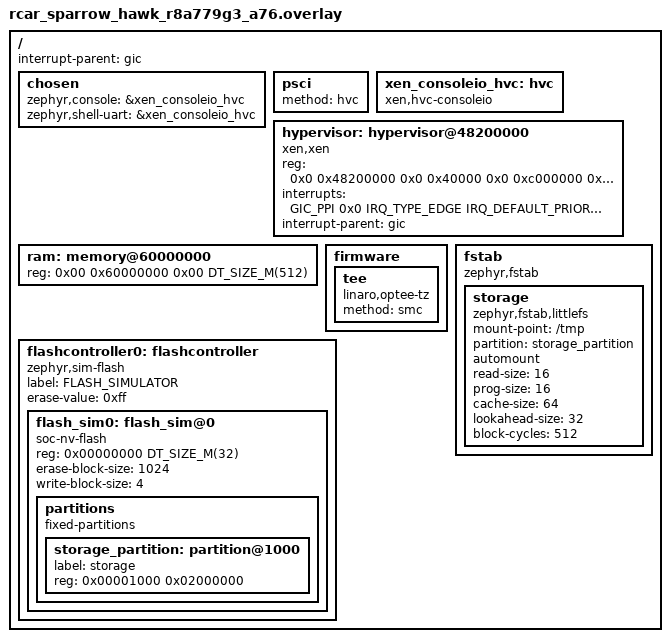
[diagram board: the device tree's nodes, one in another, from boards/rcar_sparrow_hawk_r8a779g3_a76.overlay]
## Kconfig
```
# Copyright (c) 2024 EPAM Systems
#
# SPDX-License-Identifier: Apache-2.0


config DOMD_ENABLE
	bool "Enable builtin Domain-U1 kernel binary"
	default n

config DOMD_UBOOT_PATH
	string "Location for Domain-U1 kernel binary"
	depends on DOMD_ENABLE
        default "\"/path/to/uboot/file\""

config DOMD_DTB_PATH
	string "Location for Domain-U1 device-tree"
	depends on DOMD_ENABLE
        default "\"/path/to/dtb/file\""

config DOMU_ENABLE
	bool "Enable builtin Domain-U1 kernel binary"
	default n

config DOMU_ZEPHYR_PATH
	string "Location for Domain-U1 kernel binary"
	depends on DOMU_ENABLE
        default "\"/path/to/uboot/file\""

config DOMU_DTB_PATH
	string "Location for Domain-U1 device-tree"
	depends on DOMU_ENABLE
        default "\"/path/to/dtb/file\""


config USE_DEFAULT_DOM_CFG
	bool "Use default guest domain cfg"
	default y
	help
	  Use default guest domain cfg from domu_cfg.c for build.
	  if not selected the guest domain cfg source file will be selected as basing
	  on board/platform:
	    dom_cfg/${BOARD}.c.
	  For example, for RPI 5 the dom_cfg/rpi_5.c will be used.

config DOM_CFG_BOARD_EXT
	string "Use extention string to determine guest domain cfg"
	depends on !USE_DEFAULT_DOM_CFG
	help
	  Use it to add extention string to determine guest domain cfg file to build.
	  The guest domain cfg source file will be selected as following:
	    dom_cfg/${BOARD}_${DOM_CFG_BOARD_EXT}.c
	  This allows to specify number of guest domain configs for the same board.
	  For example:
	    rpi_5_xenvm.c
	    rpi_5_domu.c

config DOM_STORAGE_FATFS_ENABLE
	bool "Enable FATFS disk storage for reading domains kernels/dtb images"
	default n
	select DISK_ACCESS
	select FILE_SYSTEM
	select FAT_FILESYSTEM_ELM
	select XRUN
	help
	  Enables FATFS disk storage and adds possibility to read guest domains
	  kernels/dtb images from storage.

if DOM_STORAGE_FATFS_ENABLE

config FS_FATFS_MOUNT_MKFS
	default n

config FS_FATFS_WINDOW_ALIGNMENT
	default SDHC_BUFFER_ALIGNMENT

config FS_FATFS_LBA64
	default y

config FS_FATFS_EXFAT
	default y

config DOM_STORAGE_FATFS_DIR
	string "FATFS folder where domains kernels/dtb images"
	default "dom0/"
	help
	  FATFS folder where domains kernels/dtb images are located.
	  It should be ended with "/" symbol.

config DOM_STORAGE_FATFS_LOGICAL_DRIVE_NAME
	string "FATFS logical drive name to be used as mount point"
	default "0" if FS_MULTI_PARTITION
	default SDMMC_VOLUME_NAME
	help
	  FATFS logical drive name to be used as mount point.

config DOM_CFG_LINUX_PV_DOMAIN
	bool "Enable PV domain support loaded from FATFS storage"
	help
	  Adds Linux-based domain with enabled pvnet and pvblock devices.
	  It is expected to be placed on the storage device, connected to
	  Dom0.

endif #DOM_STORAGE_FATFS_ENABLE

config DOM_CFG_BUILTIN_IMAGES
	bool "Use built-in guest domains kernel/device-tree images"
	default y
	help
	  Use built-in guest domains kernel/device-tree images.

if DOM_CFG_BUILTIN_IMAGES

config DOM_CFG_DOMU0_IMAGE_BIN_FILE
	string "Location for Domain-U0 kernel binary"
	default "domu0_img.bin"

config DOM_CFG_DOMU0_DTB_BIN_FILE
	string "Location for Domain-U0 device-tree"
	default "domu0.dtb"

config DOM_CFG_DOMU1_ENABLE
	bool "Enable builtin Domain-U1 kernel binary"
	default n

config DOM_CFG_DOMU1_IMAGE_BIN_FILE
	string "Location for Domain-U1 kernel binary"
	depends on DOM_CFG_DOMU1_ENABLE

config DOM_CFG_DOMU1_DTB_BIN_FILE
	string "Location for Domain-U1 device-tree"
	depends on DOM_CFG_DOMU1_ENABLE

endif #DOM_CFG_BUILTIN_IMAGES

config DOM_COVERAGE_ENABLE
	bool "Enable code coverage with GCOV"
	depends on SHELL
	select FORCE_COVERAGE
	select COVERAGE
	help
	  Enable code coverage with GCOV and enable shell command to print GCOV
	  dump "gcov dump" in console.

config VCHAN_SHELL_CMDS
	depends on SHELL
	bool "Enable VCHAN echo server shell commands"
	help
	  Enable set of VCHAN echo server shell commands. All data incoming to
	  channel created by this server will be send back. This is for test
	  purposes. Server introduces 2 commands:
	  vchan start [domid]
	    Start echo server. domid - The peer domain that will be connecting
	    (0 by default)
	  vchan stop
	    Stop server

if VCHAN_SHELL_CMDS

config VCHAN_ECHO_BUFFER_SIZE
	int "Buffer size for echo server"
	default 10

config VCHAN_THREAD_STACK_SIZE
	int "vchan echo server thread size"
	default 2048

endif #VCHAN_SHELL_CMDS

source "Kconfig.zephyr"
```

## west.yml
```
# SPDX-License-Identifier: Apache-2.0
# West YAML manifest for Zephyr as Xen Dom0

manifest:
  self:
    path: zephyr-dom0-xt

  remotes:
    - name: xentroops
      url-base: https://github.com/xen-troops/
    - name: zephyrproject-rtos
      url-base: https://github.com/zephyrproject-rtos/
    - name: yhamamachi
      url-base: https://github.com/yhamamachi/
    - name: soburi
      url-base: https://github.com/soburi/

  projects:
    - name: zephyr
      remote: yhamamachi
      revision: v4.3.0-sh
      west-commands: scripts/west-commands.yml
    - name: zephyr-xenlib
      remote: soburi
      revision: integrate-to-zephyr-repo
    - name: fatfs
      remote: zephyrproject-rtos
      revision: 427159bf95ea49b7680facffaa29ad506b42709b
    - name: zephyr-xrun
      remote: xentroops
      revision: main
```

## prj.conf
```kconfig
CONFIG_XEN_DOM0=y
CONFIG_UART_INTERRUPT_DRIVEN=n
CONFIG_SHELL_BACKEND_SERIAL_INTERRUPT_DRIVEN=n

CONFIG_MP_MAX_NUM_CPUS=1
CONFIG_XEN_STORE_SRV=y
CONFIG_XEN_DOMAIN_MANAGEMENT=y
CONFIG_XEN_SHELL=y
CONFIG_XEN_CONSOLE_SRV=y
CONFIG_HEAP_MEM_POOL_SIZE=2097152
CONFIG_SHELL_STACK_SIZE=4096

CONFIG_LOG=y
CONFIG_LOG_MODE_MINIMAL=y
CONFIG_XEN_DOMCTL_INTERFACE_VERSION=0x16
#CONFIG_LOG_DEFAULT_LEVEL=4
```

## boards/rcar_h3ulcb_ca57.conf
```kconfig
#
# Copyright (c) 2023 EPAM Systems
#
# SPDX-License-Identifier: Apache-2.0
#

# Kernel virtual memory size

# CONFIG_KERNEL_VM_SIZE=0x4000000
# CONFIG_PARTIAL_DEVICE_TREE_SIZE=80000
# 
# CONFIG_SHELL_STACK_SIZE=8192
# 
# CONFIG_XEN_DOM0=y

CONFIG_XEN_DOM0=y

CONFIG_XSTAT=y
CONFIG_XSTAT_SHELL_CMDS=y

CONFIG_SHELL_STACK_SIZE=4096

CONFIG_MAIN_STACK_SIZE=8192
CONFIG_ISR_STACK_SIZE=8192

CONFIG_XEN_VCH=y
#CONFIG_XEN_DOM0LESS_BOOT=y

CONFIG_USE_DEFAULT_DOM_CFG=n
CONFIG_DOM_CFG_BUILTIN_IMAGES=n

CONFIG_FILE_SYSTEM_SHELL=y

CONFIG_XRUN_STORAGE_DMA_DEBOUNCE=4

CONFIG_DOM_MAX=5
CONFIG_SHELL=y

CONFIG_NOCACHE_MEMORY=y
CONFIG_XEN_LIBFDT=y
CONFIG_PARTIAL_DEVICE_TREE_SIZE=1024000
```

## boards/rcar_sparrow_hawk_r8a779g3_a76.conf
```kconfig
#
# Copyright (c) 2023 EPAM Systems
#
# SPDX-License-Identifier: Apache-2.0
#

# Kernel virtual memory size

# CONFIG_KERNEL_VM_SIZE=0x4000000
# CONFIG_PARTIAL_DEVICE_TREE_SIZE=80000
# 
# CONFIG_SHELL_STACK_SIZE=8192
# 
# CONFIG_XEN_DOM0=y

CONFIG_XEN_DOM0=y

CONFIG_XSTAT=y
CONFIG_XSTAT_SHELL_CMDS=y

CONFIG_SHELL_STACK_SIZE=4096

CONFIG_MAIN_STACK_SIZE=8192
CONFIG_ISR_STACK_SIZE=8192

CONFIG_XEN_VCH=y
#CONFIG_XEN_DOM0LESS_BOOT=y

CONFIG_USE_DEFAULT_DOM_CFG=n
CONFIG_DOM_CFG_BUILTIN_IMAGES=n

CONFIG_FILE_SYSTEM_SHELL=y

CONFIG_XRUN_STORAGE_DMA_DEBOUNCE=4

CONFIG_DOMU_MAX=5
CONFIG_SHELL=y
CONFIG_DEBUG=y

CONFIG_NOCACHE_MEMORY=y
CONFIG_XEN_LIBFDT=y
CONFIG_PARTIAL_DEVICE_TREE_SIZE=1024000
```

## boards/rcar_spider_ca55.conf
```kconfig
#
# Copyright (c) 2023 EPAM Systems
#
# SPDX-License-Identifier: Apache-2.0
#

# Kernel virtual memory size

# CONFIG_KERNEL_VM_SIZE=0x4000000
# CONFIG_PARTIAL_DEVICE_TREE_SIZE=80000
# 
# CONFIG_SHELL_STACK_SIZE=8192
# 
# CONFIG_XEN_DOM0=y

CONFIG_XEN_DOM0=y

CONFIG_XSTAT=y
CONFIG_XSTAT_SHELL_CMDS=y

CONFIG_SHELL_STACK_SIZE=4096

CONFIG_MAIN_STACK_SIZE=8192
CONFIG_ISR_STACK_SIZE=8192

CONFIG_XEN_VCH=y
#CONFIG_XEN_DOM0LESS_BOOT=y

CONFIG_USE_DEFAULT_DOM_CFG=n
CONFIG_DOM_CFG_BUILTIN_IMAGES=n

CONFIG_FILE_SYSTEM_SHELL=y

CONFIG_XRUN_STORAGE_DMA_DEBOUNCE=4

CONFIG_DOM_MAX=5
CONFIG_SHELL=y

CONFIG_NOCACHE_MEMORY=y
CONFIG_XEN_LIBFDT=y
CONFIG_PARTIAL_DEVICE_TREE_SIZE=1024000
```

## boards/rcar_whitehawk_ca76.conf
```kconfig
#
# Copyright (c) 2023 EPAM Systems
#
# SPDX-License-Identifier: Apache-2.0
#

# Kernel virtual memory size

# CONFIG_KERNEL_VM_SIZE=0x4000000
# CONFIG_PARTIAL_DEVICE_TREE_SIZE=80000
# 
# CONFIG_SHELL_STACK_SIZE=8192
# 
# CONFIG_XEN_DOM0=y

CONFIG_XEN_DOM0=y

CONFIG_XSTAT=y
CONFIG_XSTAT_SHELL_CMDS=y

CONFIG_SHELL_STACK_SIZE=4096

CONFIG_MAIN_STACK_SIZE=8192
CONFIG_ISR_STACK_SIZE=8192

CONFIG_XEN_VCH=y
#CONFIG_XEN_DOM0LESS_BOOT=y

CONFIG_USE_DEFAULT_DOM_CFG=n
CONFIG_DOM_CFG_BUILTIN_IMAGES=n

CONFIG_FILE_SYSTEM_SHELL=y

CONFIG_XRUN_STORAGE_DMA_DEBOUNCE=4

CONFIG_DOM_MAX=5
CONFIG_SHELL=y
CONFIG_DEBUG=y

CONFIG_NOCACHE_MEMORY=y
CONFIG_XEN_LIBFDT=y
CONFIG_PARTIAL_DEVICE_TREE_SIZE=1024000
```

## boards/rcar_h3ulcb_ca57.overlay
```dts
/*
 * Copyright (C) 2023 Renesas Electronics Corporation.
 * Copyright (C) 2023 EPAM Systems, Inc.
 *
 * SPDX-License-Identifier: Apache-2.0
 */

#include <mem.h>

/delete-node/ &ram;

// &mmc0 {
// 	disk {
// 		status = "okay";
// 	};
// 	status = "okay";
// };

/ {
	/*
	 * This node may differs on different setups, please check
	 * following line in Xen boot log to set it right:
	 * (XEN) Grant table range: 0x00000078080000-0x000000780c0000
	 * Also, add extended region 1:
	 * (XEN) Extended region 1: 0x40000000->0x47e00000
	 *
	 * Xen passes actual values for setup in domain device tree, but Zephyr
	 * is not capable to parse and handle it in runtime.
	 */
	hypervisor: hypervisor@88080000 {
		compatible = "xen,xen";
		reg = <0x0 0x88080000 0x0 0x40000 0x0 0x40000000 0x0 0x7e00000>;
		interrupts = <GIC_PPI 0x0 IRQ_TYPE_EDGE IRQ_DEFAULT_PRIORITY>;
		interrupt-parent = <&gic>;
		status = "okay";
	};

	/*
	 * This node may differs on different setups, because Xen picks
	 * region for Domain-0 for every specific configuration. You can
	 * start Xen for your platform and check following log:
	 * (XEN) Allocating 1:1 mappings for dom0:
	 * (XEN) BANK[0] 0x00000080000000-0x00000090000000 (256MB)
	 *
	 * Xen passes actual values for setup in domain device tree, but Zephyr
	 * is not capable to parse and handle it in runtime.
	 */
	ram: memory@70000000 {
		device_type = "mmio-sram";
		reg = <0x00 0x70000000 0x00 DT_SIZE_M(256)>;
	};

	firmware {
		tee {
		compatible = "linaro,optee-tz";
		method = "smc";
		status = "okay";
		};
	};

	fstab {
		compatible = "zephyr,fstab";
		storage: storage {
			compatible = "zephyr,fstab,littlefs";
			mount-point = "/tmp";
			partition = <&storage_partition>;
			automount;
			read-size = <16>;
			prog-size = <16>;
			cache-size = <64>;
			lookahead-size = <32>;
			block-cycles = <512>;
		};
	};

	flashcontroller0: flashcontroller {
		compatible = "zephyr,sim-flash";
		label = "FLASH_SIMULATOR";
		#address-cells = <1>;
		#size-cells = <1>;
		erase-value = <0xff>;
		flash_sim0: flash_sim@0 {
			compatible = "soc-nv-flash";
			reg = <0x00000000 DT_SIZE_M(32)>;
			erase-block-size = <1024>;
			write-block-size = <4>;
			partitions {
				compatible = "fixed-partitions";
				#address-cells = <1>;
				#size-cells = <1>;
				/*
				* Storage partition will be used by FCB/LittleFS/NVS
				* if enabled.
				*/
				storage_partition: partition@1000 {
					label = "storage";
					reg = <0x00001000 0x02000000>;
				};
			};
		};
	};
};
```

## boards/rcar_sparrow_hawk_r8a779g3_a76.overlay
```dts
/*
 * Copyright (C) 2023 Renesas Electronics Corporation.
 * Copyright (C) 2023 EPAM Systems, Inc.
 *
 * SPDX-License-Identifier: Apache-2.0
 */

#include <mem.h>

/delete-node/ &ram;
/delete-node/ &scif1;

// &mmc0 {
// 	disk {
// 		status = "okay";
// 	};
// 	status = "okay";
// };

/ {
	/* from xen_dom0 snippets */
	interrupt-parent = <&gic>;
	#address-cells = <2>;
	#size-cells = <2>;

	chosen {
		zephyr,console = &xen_consoleio_hvc;
		zephyr,shell-uart = &xen_consoleio_hvc;
	};

	psci {
		method = "hvc";
	};

	xen_consoleio_hvc: hvc {
		compatible = "xen,hvc-consoleio";
		status = "okay";
	};

	/*
	 * This node may differs on different setups, please check
	 * following line in Xen boot log to set it right:
	 * (XEN) Grant table range: 0x00000078080000-0x000000780c0000
	 * Also, add extended region 1:
	 * (XEN) Extended region 1: 0x40000000->0x47e00000
         * V4H
         * (XEN) Grant table range: 0x00000078080000-0x000000780c0000
         * (snip)
         * (XEN) d0: extended region 0: 0->0x7e00000
	 * (XEN) d0: extended region 1: 0xc000000->0x2fe00000
	 * Xen passes actual values for setup in domain device tree, but Zephyr
	 * is not capable to parse and handle it in runtime.
	 */
	hypervisor: hypervisor@48200000 {
		compatible = "xen,xen";
		reg = <0x0 0x48200000 0x0 0x40000 0x0 0xc000000 0x0 0x23e00000>;
		interrupts = <GIC_PPI 0x0 IRQ_TYPE_EDGE IRQ_DEFAULT_PRIORITY>;
		interrupt-parent = <&gic>;
		status = "okay";
	};

	/*
	 * This node may differs on different setups, because Xen picks
	 * region for Domain-0 for every specific configuration. You can
	 * start Xen for your platform and check following log:
	 * (XEN) Allocating 1:1 mappings for dom0:
	 * (XEN) BANK[0] 0x00000080000000-0x00000090000000 (256MB)
	 *
	 * Xen passes actual values for setup in domain device tree, but Zephyr
	 * is not capable to parse and handle it in runtime.
	 */
	ram: memory@60000000 {
		device_type = "mmio-sram";
		reg = <0x00 0x60000000 0x00 DT_SIZE_M(512)>;
	};

	firmware {
		tee {
		compatible = "linaro,optee-tz";
		method = "smc";
		status = "okay";
		};
	};

	fstab {
		compatible = "zephyr,fstab";
		storage: storage {
			compatible = "zephyr,fstab,littlefs";
			mount-point = "/tmp";
			partition = <&storage_partition>;
			automount;
			read-size = <16>;
			prog-size = <16>;
			cache-size = <64>;
			lookahead-size = <32>;
			block-cycles = <512>;
		};
	};

	flashcontroller0: flashcontroller {
		compatible = "zephyr,sim-flash";
		label = "FLASH_SIMULATOR";
		#address-cells = <1>;
		#size-cells = <1>;
		erase-value = <0xff>;
		flash_sim0: flash_sim@0 {
			compatible = "soc-nv-flash";
			reg = <0x00000000 DT_SIZE_M(32)>;
			erase-block-size = <1024>;
			write-block-size = <4>;
			partitions {
				compatible = "fixed-partitions";
				#address-cells = <1>;
				#size-cells = <1>;
				/*
				* Storage partition will be used by FCB/LittleFS/NVS
				* if enabled.
				*/
				storage_partition: partition@1000 {
					label = "storage";
					reg = <0x00001000 0x02000000>;
				};
			};
		};
	};
};
```

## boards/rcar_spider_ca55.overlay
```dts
/*
 * Copyright (C) 2023 Renesas Electronics Corporation.
 * Copyright (C) 2023 EPAM Systems, Inc.
 *
 * SPDX-License-Identifier: Apache-2.0
 */

#include <mem.h>

/delete-node/ &ram;

// &mmc0 {
// 	disk {
// 		status = "okay";
// 	};
// 	status = "okay";
// };

/ {
	/*
	 * This node may differs on different setups, please check
	 * following line in Xen boot log to set it right:
	 * (XEN) Grant table range: 0x00000078080000-0x000000780c0000
	 * Also, add extended region 1:
	 * (XEN) Extended region 1: 0x40000000->0x47e00000
	 *
	 * Xen passes actual values for setup in domain device tree, but Zephyr
	 * is not capable to parse and handle it in runtime.
	 */
	hypervisor: hypervisor@78080000 {
		compatible = "xen,xen";
		reg = <0x0 0x78080000 0x0 0x40000 0x0 0x40000000 0x0 0x7e00000>;
		interrupts = <GIC_PPI 0x0 IRQ_TYPE_EDGE IRQ_DEFAULT_PRIORITY>;
		interrupt-parent = <&gic>;
		status = "okay";
	};

	/*
	 * This node may differs on different setups, because Xen picks
	 * region for Domain-0 for every specific configuration. You can
	 * start Xen for your platform and check following log:
	 * (XEN) Allocating 1:1 mappings for dom0:
	 * (XEN) BANK[0] 0x00000080000000-0x00000090000000 (256MB)
	 *
	 * Xen passes actual values for setup in domain device tree, but Zephyr
	 * is not capable to parse and handle it in runtime.
	 */
	ram: memory@90000000 {
		device_type = "mmio-sram";
		reg = <0x00 0x90000000 0x00 DT_SIZE_M(256)>;
	};

	firmware {
		tee {
		compatible = "linaro,optee-tz";
		method = "smc";
		status = "okay";
		};
	};

	fstab {
		compatible = "zephyr,fstab";
		storage: storage {
			compatible = "zephyr,fstab,littlefs";
			mount-point = "/tmp";
			partition = <&storage_partition>;
			automount;
			read-size = <16>;
			prog-size = <16>;
			cache-size = <64>;
			lookahead-size = <32>;
			block-cycles = <512>;
		};
	};

	flashcontroller0: flashcontroller {
		compatible = "zephyr,sim-flash";
		label = "FLASH_SIMULATOR";
		#address-cells = <1>;
		#size-cells = <1>;
		erase-value = <0xff>;
		flash_sim0: flash_sim@0 {
			compatible = "soc-nv-flash";
			reg = <0x00000000 DT_SIZE_M(32)>;
			erase-block-size = <1024>;
			write-block-size = <4>;
			partitions {
				compatible = "fixed-partitions";
				#address-cells = <1>;
				#size-cells = <1>;
				/*
				* Storage partition will be used by FCB/LittleFS/NVS
				* if enabled.
				*/
				storage_partition: partition@1000 {
					label = "storage";
					reg = <0x00001000 0x02000000>;
				};
			};
		};
	};
};
```

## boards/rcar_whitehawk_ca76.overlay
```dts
/*
 * Copyright (C) 2023 Renesas Electronics Corporation.
 * Copyright (C) 2023 EPAM Systems, Inc.
 *
 * SPDX-License-Identifier: Apache-2.0
 */

#include <mem.h>

/delete-node/ &ram;

// &mmc0 {
// 	disk {
// 		status = "okay";
// 	};
// 	status = "okay";
// };

/ {
	/*
	 * This node may differs on different setups, please check
	 * following line in Xen boot log to set it right:
	 * (XEN) Grant table range: 0x00000078080000-0x000000780c0000
	 * Also, add extended region 1:
	 * (XEN) Extended region 1: 0x40000000->0x47e00000
         * V4H
         * (XEN) Grant table range: 0x00000078080000-0x000000780c0000
         * (snip)
         * (XEN) d0: extended region 0: 0->0x7e00000
	 * (XEN) d0: extended region 1: 0xc000000->0x2fe00000
	 * Xen passes actual values for setup in domain device tree, but Zephyr
	 * is not capable to parse and handle it in runtime.
	 */
	hypervisor: hypervisor@78080000 {
		compatible = "xen,xen";
		reg = <0x0 0x78080000 0x0 0x40000 0x0 0xc000000 0x0 0x23e00000>;
		interrupts = <GIC_PPI 0x0 IRQ_TYPE_EDGE IRQ_DEFAULT_PRIORITY>;
		interrupt-parent = <&gic>;
		status = "okay";
	};

	/*
	 * This node may differs on different setups, because Xen picks
	 * region for Domain-0 for every specific configuration. You can
	 * start Xen for your platform and check following log:
	 * (XEN) Allocating 1:1 mappings for dom0:
	 * (XEN) BANK[0] 0x00000080000000-0x00000090000000 (256MB)
	 *
	 * Xen passes actual values for setup in domain device tree, but Zephyr
	 * is not capable to parse and handle it in runtime.
	 */
	ram: memory@60000000 {
		device_type = "mmio-sram";
		reg = <0x00 0x60000000 0x00 DT_SIZE_M(256)>;
	};

	firmware {
		tee {
		compatible = "linaro,optee-tz";
		method = "smc";
		status = "okay";
		};
	};

	fstab {
		compatible = "zephyr,fstab";
		storage: storage {
			compatible = "zephyr,fstab,littlefs";
			mount-point = "/tmp";
			partition = <&storage_partition>;
			automount;
			read-size = <16>;
			prog-size = <16>;
			cache-size = <64>;
			lookahead-size = <32>;
			block-cycles = <512>;
		};
	};

	flashcontroller0: flashcontroller {
		compatible = "zephyr,sim-flash";
		label = "FLASH_SIMULATOR";
		#address-cells = <1>;
		#size-cells = <1>;
		erase-value = <0xff>;
		flash_sim0: flash_sim@0 {
			compatible = "soc-nv-flash";
			reg = <0x00000000 DT_SIZE_M(32)>;
			erase-block-size = <1024>;
			write-block-size = <4>;
			partitions {
				compatible = "fixed-partitions";
				#address-cells = <1>;
				#size-cells = <1>;
				/*
				* Storage partition will be used by FCB/LittleFS/NVS
				* if enabled.
				*/
				storage_partition: partition@1000 {
					label = "storage";
					reg = <0x00001000 0x02000000>;
				};
			};
		};
	};
};
```

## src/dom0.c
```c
/*
 * Copyright (c) 2024 EPAM Systems
 *
 * SPDX-License-Identifier: Apache-2.0
 */

#include <domain.h>
#include <zephyr/kernel.h>
#include <zephyr/logging/log.h>

LOG_MODULE_REGISTER(dom0);

#include "dom0.h"

extern struct dom0_domain_cfg domain_cfgs[];
#ifdef CONFIG_DOMD_ENABLE
extern struct xen_domain_cfg domd_cfg;
#endif
#ifdef CONFIG_DOMU_ENABLE
extern struct xen_domain_cfg domu_cfg;
#endif

int domain_get_user_cfg_count(void)
{
	int i = 0;

	while (domain_cfgs[i].domain_cfg) {
		i++;
	}

	return i;
}

struct xen_domain_cfg *domain_get_user_cfg(int index)
{
	if (index < domain_get_user_cfg_count()) {
		return domain_cfgs[index].domain_cfg;
	}

	return NULL;
}

int main(void)
{
	int i = 0;
        LOG_INF("dom0.c: main function: start");
/*
	ret = storage_init();
	if (ret) {
		goto exit_err;
	}
*/
	/* It's required to init xenlib struct xen_domain_cfg->image_info with pointer
	 * at struct dom0_domain_cfg, so it can be passed in binary images loading callbacks like
	 * .load_image_bytes()/get_image_size(). It's the only way to pass app data
	 * back from xenlib.
	 */
	while (domain_cfgs[i].domain_cfg) {
		if (domain_cfgs[i].init) {
			domain_cfgs[i].init();
		}
		domain_cfgs[i].domain_cfg->image_info = &domain_cfgs[i];
		i++;
	}
#ifdef CONFIG_DOMD_ENABLE
        domain_create(&domd_cfg, 1);
#endif
#ifdef CONFIG_DOMU_ENABLE
        //domain_create(&domu_cfg, 1);
#endif
        LOG_INF("dom0.c: main function: end");
        printf("Hello from Dom0\n");
	return 0;
}
```

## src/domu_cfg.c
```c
/*
 * Copyright (c) 2023 EPAM Systems
 *
 * SPDX-License-Identifier: Apache-2.0
 */

#include <domain.h>
#include <zephyr/xen/public/domctl.h>
#include <zephyr/xen/public/arch-arm.h>

#include <string.h>

#include "dom0.h"

extern char __img_domu0_start[];
extern char __img_domu0_end[];
extern char __dtb_domu0_start[];
extern char __dtb_domu0_end[];

static int load_domu_image_bytes(uint8_t *buf, size_t bufsize,
		   uint64_t offset, void *image_info)
{
	ARG_UNUSED(image_info);

	memcpy(buf, __img_domu0_start + offset, bufsize);
	return 0;
}

static ssize_t get_domu_image_size(void *image_info, uint64_t *size)
{
	ARG_UNUSED(image_info);

	*size = __img_domu0_end - __img_domu0_start;
	return 0;
}

static struct xen_domain_cfg domu_cfg = {
	.name = "domu_default",
	.mem_kb = 16384,

	.flags = (XEN_DOMCTL_CDF_hvm | XEN_DOMCTL_CDF_hap),
	.max_evtchns = 10,
	.max_vcpus = 4,
	.gnt_frames = 32,
	.max_maptrack_frames = 1,

	.gic_version =
		IS_ENABLED(CONFIG_GIC_V3) ? XEN_DOMCTL_CONFIG_GIC_V3 : XEN_DOMCTL_CONFIG_GIC_V2,
	.tee_type = XEN_DOMCTL_CONFIG_TEE_NONE,

	.load_image_bytes = load_domu_image_bytes,
	.get_image_size = get_domu_image_size,

	.dtb_start = __dtb_domu0_start,
	.dtb_end = __dtb_domu0_end,
};

struct dom0_domain_cfg domain_cfgs[] = {
	{
		.domain_cfg = &domu_cfg,
	},
	{ 0 },
};
```
